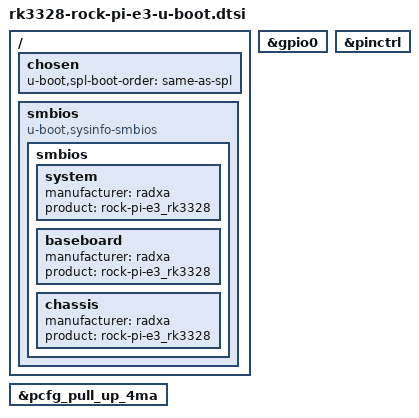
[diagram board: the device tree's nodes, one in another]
// SPDX-License-Identifier: GPL-2.0+
/*
 * (C) Copyright 2020 Radxa
 */

#include "rk3328-u-boot.dtsi"
#include "rk3328-sdram-lpddr3-1600.dtsi"

/ {
	chosen {
		u-boot,spl-boot-order = "same-as-spl", &sdmmc, &emmc;
	};

	smbios {
		compatible = "u-boot,sysinfo-smbios";

		smbios {
			system {
				manufacturer = "radxa";
				product = "rock-pi-e3_rk3328";
			};

			baseboard {
				manufacturer = "radxa";
				product = "rock-pi-e3_rk3328";
			};

			chassis {
				manufacturer = "radxa";
				product = "rock-pi-e3_rk3328";
			};
		};
	};
};

&gpio0 {
	u-boot,dm-spl;
};

&pinctrl {
	u-boot,dm-spl;
};

&pcfg_pull_up_4ma {
	u-boot,dm-spl;
};
